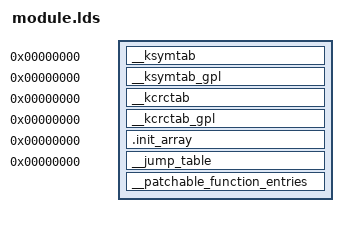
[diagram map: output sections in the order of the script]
SECTIONS {
 /DISCARD/ : {
  *(.discard)
  *(.discard.*)
 }
 __ksymtab 0 : { *(SORT(___ksymtab+*)) }
 __ksymtab_gpl 0 : { *(SORT(___ksymtab_gpl+*)) }
 __kcrctab 0 : { *(SORT(___kcrctab+*)) }
 __kcrctab_gpl 0 : { *(SORT(___kcrctab_gpl+*)) }
 .init_array 0 : ALIGN(8) { *(SORT(.init_array.*)) *(.init_array) }
 __jump_table 0 : ALIGN(8) { KEEP(*(__jump_table)) }
 __patchable_function_entries : { *(__patchable_function_entries) }
}
